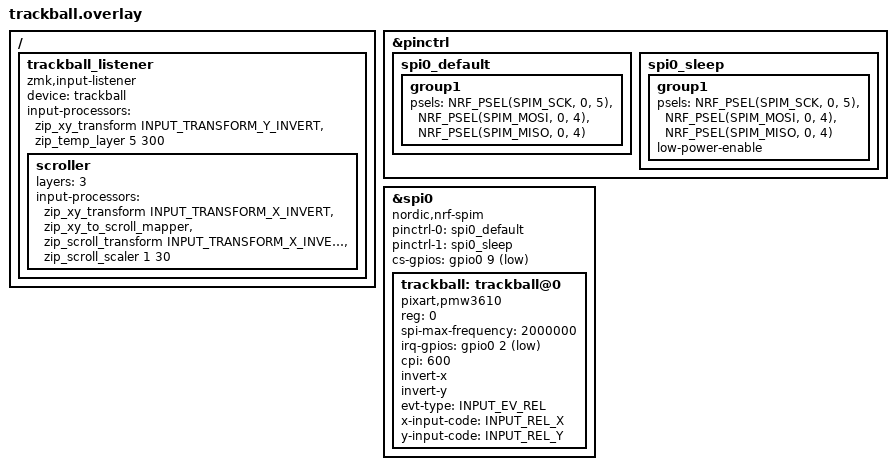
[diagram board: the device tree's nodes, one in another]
#include <input/processors.dtsi>
#include <dt-bindings/zmk/input_transform.h>
#include <zephyr/dt-bindings/input/input-event-codes.h>


&pinctrl {
    spi0_default: spi0_default {    //通常時(SPI通信中)のピン構成
        group1 {
            psels = <NRF_PSEL(SPIM_SCK, 0, 5)>, //P0.05を指定(SCLK)
                <NRF_PSEL(SPIM_MOSI, 0, 4)>,    //P0.04を指定(SDIOだからMOSI,MISO両方の役割を担う)
                <NRF_PSEL(SPIM_MISO, 0, 4)>;
        };
    };

    spi0_sleep: spi0_sleep {    //スリープ時のピン構成(省電力)
        group1 {
            psels = <NRF_PSEL(SPIM_SCK, 0, 5)>,
                <NRF_PSEL(SPIM_MOSI, 0, 4)>,
                <NRF_PSEL(SPIM_MISO, 0, 4)>;
            low-power-enable;
        };
    };
};


&spi0 {
    status = "okay";
    compatible = "nordic,nrf-spim"; //マイコンがnRFシリーズ
    pinctrl-0 = <&spi0_default>;
    pinctrl-1 = <&spi0_sleep>;
    pinctrl-names = "default", "sleep";
    cs-gpios = <&gpio0 9 GPIO_ACTIVE_LOW>;  //P0.09を指定(CS)

    trackball: trackball@0 {
        status = "okay";
        compatible = "pixart,pmw3610";  //トラボセンサ用のドライバとバインド
        reg = <0>;
        spi-max-frequency = <2000000>;
        irq-gpios = <&gpio0 2 (GPIO_ACTIVE_LOW | GPIO_PULL_UP)>; //P0.02を指定(MOTION)
        cpi = <600>;
        //swap-xy;
        invert-x; //COROPIT版ではコメントアウトを外す
        invert-y; //COROPIT版ではコメントアウトを外す
        evt-type = <INPUT_EV_REL>;
        x-input-code = <INPUT_REL_X>;
        y-input-code = <INPUT_REL_Y>;
    };
};


/ {
    trackball_listener: trackball_listener {
        compatible = "zmk,input-listener";
        status = "okay";
        device = <&trackball>;
        input-processors =
            <&zip_xy_transform INPUT_TRANSFORM_Y_INVERT>,         //Y軸反転
            <&zip_temp_layer 5 300>;                              //オートマウスレイヤーの選択

        scroller {
            layers = <3>;
            input-processors =
                <&zip_xy_transform INPUT_TRANSFORM_X_INVERT>,       //X軸反転
                <&zip_xy_to_scroll_mapper>,                         //スクロールモードに変更
                <&zip_scroll_transform INPUT_TRANSFORM_X_INVERT>,   //スクロールのX軸反転
                <&zip_scroll_scaler 1 30>;                          //スクロール量を1/30倍
        };
    };
};
